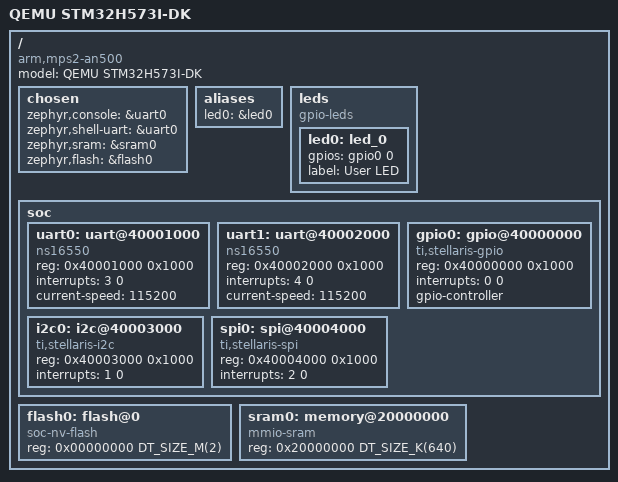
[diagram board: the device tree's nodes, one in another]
/*
 * Copyright (c) 2025 CRUSTy-Core
 *
 * SPDX-License-Identifier: Apache-2.0
 */

/dts-v1/;
#include <arm/armv7-m.dtsi>
#include <zephyr/dt-bindings/i2c/i2c.h>

/ {
	model = "QEMU STM32H573I-DK";
	compatible = "arm,mps2-an500", "qemu,stm32h573i-dk";

	chosen {
		zephyr,console = &uart0;
		zephyr,shell-uart = &uart0;
		zephyr,sram = &sram0;
		zephyr,flash = &flash0;
	};

	aliases {
		led0 = &led0;
	};

	leds {
		compatible = "gpio-leds";
		led0: led_0 {
			gpios = <&gpio0 0 0>;
			label = "User LED";
		};
	};

	soc {
		uart0: uart@40001000 {
			compatible = "ns16550";
			reg = <0x40001000 0x1000>;
			interrupts = <3 0>;
			status = "okay";
			current-speed = <115200>;
		};

		uart1: uart@40002000 {
			compatible = "ns16550";
			reg = <0x40002000 0x1000>;
			interrupts = <4 0>;
			status = "okay";
			current-speed = <115200>;
		};

		gpio0: gpio@40000000 {
			compatible = "ti,stellaris-gpio";
			reg = <0x40000000 0x1000>;
			interrupts = <0 0>;
			gpio-controller;
			#gpio-cells = <2>;
		};

		i2c0: i2c@40003000 {
			compatible = "ti,stellaris-i2c";
			reg = <0x40003000 0x1000>;
			interrupts = <1 0>;
			status = "okay";
			#address-cells = <1>;
			#size-cells = <0>;
		};

		spi0: spi@40004000 {
			compatible = "ti,stellaris-spi";
			reg = <0x40004000 0x1000>;
			interrupts = <2 0>;
			status = "okay";
			#address-cells = <1>;
			#size-cells = <0>;
		};
	};

	flash0: flash@0 {
		compatible = "soc-nv-flash";
		reg = <0x00000000 DT_SIZE_M(2)>;
	};

	sram0: memory@20000000 {
		compatible = "mmio-sram";
		reg = <0x20000000 DT_SIZE_K(640)>;
	};
};
